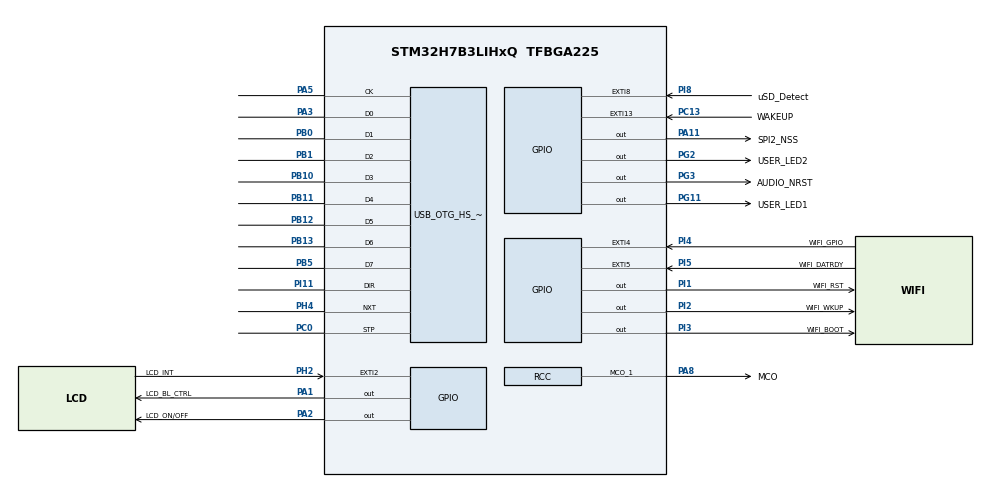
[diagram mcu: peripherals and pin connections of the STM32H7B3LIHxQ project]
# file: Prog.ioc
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Mcu.Family=STM32H7
Mcu.Name=STM32H7B3LIHxQ
Mcu.Package=TFBGA225
NVIC.PriorityGroup=NVIC_PRIORITYGROUP_4
PA1.GPIO_Label=LCD_BL_CTRL
PA1.PinState=GPIO_PIN_SET
PA1.Signal=GPIO_Output
PA10.GPIO_Label=VCP_RX
PA10.Signal=USART1_RX
PA11.GPIO_Label=SPI2_NSS
PA11.Signal=GPIO_Output
PA12.GPIO_Label=SPI2_SCK
PA12.Signal=SPI2_SCK
PA13.GPIO_Label=JTMS
PA13.Mode=JTAG_5_pins
PA13.Signal=DEBUG_JTMS-SWDIO
PA14.GPIO_Label=JTCK
PA14.Mode=JTAG_5_pins
PA14.Signal=DEBUG_JTCK-SWCLK
PA15.GPIO_Label=JTDI
PA15.Mode=JTAG_5_pins
PA15.Signal=DEBUG_JTDI
PA2.GPIO_Label=LCD_ON/OFF
PA2.PinState=GPIO_PIN_SET
PA2.Signal=GPIO_Output
PA3.Mode=Device_HS
PA3.Signal=USB_OTG_HS_ULPI_D0
PA5.Mode=Device_HS
PA5.Signal=USB_OTG_HS_ULPI_CK
PA8.GPIO_Label=MCO
PA8.Mode=Clock-out-1
PA8.Signal=RCC_MCO_1
PA9.GPIO_Label=VCP_TX
PA9.Signal=USART1_TX
PB0.Mode=Device_HS
PB0.Signal=USB_OTG_HS_ULPI_D1
PB1.Mode=Device_HS
PB1.Signal=USB_OTG_HS_ULPI_D2
PB10.Mode=Device_HS
PB10.Signal=USB_OTG_HS_ULPI_D3
PB11.Mode=Device_HS
PB11.Signal=USB_OTG_HS_ULPI_D4
PB12.Mode=Device_HS
PB12.Signal=USB_OTG_HS_ULPI_D5
PB13.Mode=Device_HS
PB13.Signal=USB_OTG_HS_ULPI_D6
PB2.GPIO_Label=OCSPI1_CLK
PB2.Signal=OCTOSPIM_P1_CLK
PB3.GPIO_Label=JTDO_TRACESWO
PB3.Mode=JTAG_5_pins
PB3.Signal=DEBUG_JTDO-SWO
PB4.Mode=JTAG_5_pins
PB4.Signal=DEBUG_JTRST
PB5.Mode=Device_HS
PB5.Signal=USB_OTG_HS_ULPI_D7
PC0.Mode=Device_HS
PC0.Signal=USB_OTG_HS_ULPI_STP
PC1.GPIO_Label=OCSPI1_IO4
PC1.Signal=OCTOSPIM_P1_IO4
PC10.GPIO_Label=SDIO1_D2
PC10.Signal=SDMMC1_D2
PC11.GPIO_Label=SDIO1_D3
PC11.Signal=SDMMC1_D3
PC12.GPIO_Label=SDIO1_CK
PC12.Signal=SDMMC1_CK
PC13.GPIO_Label=WAKEUP
PC13.Signal=GPXTI13
PC14-OSC32_IN.Mode=LSE-External-Oscillator
PC14-OSC32_IN.Signal=RCC_OSC32_IN
PC15-OSC32_OUT.Mode=LSE-External-Oscillator
PC15-OSC32_OUT.Signal=RCC_OSC32_OUT
PC2.GPIO_Label=SPI2_MISO
PC2.Signal=SPI2_MISO
PC3.GPIO_Label=SPI2_MOSI
PC3.Signal=SPI2_MOSI
PC5.GPIO_Label=OCSPI1_DQS
PC5.Signal=OCTOSPIM_P1_DQS
PC8.GPIO_Label=SDIO1_D0
PC8.Signal=SDMMC1_D0
PC9.GPIO_Label=SDIO1_D1
PC9.Signal=SDMMC1_D1
PD0.GPIO_Label=D2
PD0.Signal=FMC_D2_DA2
PD1.GPIO_Label=D3
PD1.Signal=FMC_D3_DA3
PD10.GPIO_Label=D15
PD10.Signal=FMC_D15_DA15
PD12.GPIO_Label=I2C4_SCL
PD12.GPIO_Pu=GPIO_PULLUP
PD12.Signal=I2C4_SCL
PD13.GPIO_Label=I2C4_SDA
PD13.GPIO_Pu=GPIO_PULLUP
PD13.Signal=I2C4_SDA
PD14.GPIO_Label=D0
PD14.Signal=FMC_D0_DA0
PD15.GPIO_Label=D1
PD15.Signal=FMC_D1_DA1
PD2.GPIO_Label=SDIO1_CMD
PD2.Signal=SDMMC1_CMD
PD7.GPIO_Label=OCSPI1_IO7
PD7.Signal=OCTOSPIM_P1_IO7
PD8.GPIO_Label=D13
PD8.Signal=FMC_D13_DA13
PD9.GPIO_Label=D14
PD9.Signal=FMC_D14_DA14
PE0.GPIO_Label=FMC_NBL0
PE0.Signal=FMC_NBL0
PE1.GPIO_Label=FMC_NBL1
PE1.Signal=FMC_NBL1
PE10.GPIO_Label=D7
PE10.Signal=FMC_D7_DA7
PE11.GPIO_Label=D8
PE11.Signal=FMC_D8_DA8
PE12.GPIO_Label=D9
PE12.Signal=FMC_D9_DA9
PE13.GPIO_Label=D10
PE13.Signal=FMC_D10_DA10
PE14.GPIO_Label=D11
PE14.Signal=FMC_D11_DA11
PE15.GPIO_Label=D12
PE15.Signal=FMC_D12_DA12
PE7.GPIO_Label=D4
PE7.Signal=FMC_D4_DA4
PE8.GPIO_Label=D5
PE8.Signal=FMC_D5_DA5
PE9.GPIO_Label=D6
PE9.Signal=FMC_D6_DA6
PF0.GPIO_Label=A0
PF0.Signal=FMC_A0
PF1.GPIO_Label=A1
PF1.Signal=FMC_A1
PF11.GPIO_Label=SDNRAS
PF11.Signal=FMC_SDNRAS
PF12.GPIO_Label=A6
PF12.Signal=FMC_A6
PF13.GPIO_Label=A7
PF13.Signal=FMC_A7
PF14.GPIO_Label=A8
PF14.Signal=FMC_A8
PF15.GPIO_Label=A9
PF15.Signal=FMC_A9
PF2.GPIO_Label=A2
PF2.Signal=FMC_A2
PF3.GPIO_Label=A3
PF3.Signal=FMC_A3
PF4.GPIO_Label=A4
PF4.Signal=FMC_A4
PF5.GPIO_Label=A5
PF5.Signal=FMC_A5
PG0.GPIO_Label=A10
PG0.Signal=FMC_A10
PG1.GPIO_Label=A11
PG1.Signal=FMC_A11
PG11.GPIO_Label=USER_LED1
PG11.Signal=GPIO_Output
PG15.GPIO_Label=SDNCAS
PG15.Signal=FMC_SDNCAS
PG2.GPIO_Label=USER_LED2
PG2.Signal=GPIO_Output
PG3.GPIO_Label=AUDIO_NRST
PG3.PinState=GPIO_PIN_SET
PG3.Signal=GPIO_Output
PG4.GPIO_Label=A14
PG4.Signal=FMC_A14_BA0
PG5.GPIO_Label=A15
PG5.Signal=FMC_A15_BA1
PG6.GPIO_Label=OCSPI1_NCS
PG6.Signal=OCTOSPIM_P1_NCS
PG8.GPIO_Label=SDCLK
PG8.Signal=FMC_SDCLK
PG9.GPIO_Label=OCSPI1_IO6
PG9.Signal=OCTOSPIM_P1_IO6
PH0-OSC_IN.Mode=HSE-External-Oscillator
PH0-OSC_IN.Signal=RCC_OSC_IN
PH1-OSC_OUT.Mode=HSE-External-Oscillator
PH1-OSC_OUT.Signal=RCC_OSC_OUT
PH2.GPIO_Label=LCD_INT
PH2.Signal=GPXTI2
PH3.GPIO_Label=OCSPI1_IO5
PH3.Signal=OCTOSPIM_P1_IO5
PH4.Mode=Device_HS
PH4.Signal=USB_OTG_HS_ULPI_NXT
PH5.GPIO_Label=SDNWE
PH5.Signal=FMC_SDNWE
PH6.GPIO_Label=SDNE1
PH6.Signal=FMC_SDNE1
PH7.GPIO_Label=SDCKE1
PH7.Signal=FMC_SDCKE1
PI1.GPIO_Label=WIFI_RST
PI1.Signal=GPIO_Output
PI11.Mode=Device_HS
PI11.Signal=USB_OTG_HS_ULPI_DIR
PI12.GPIO_Label=LCD_HSYNC
PI12.Signal=LTDC_HSYNC
PI13.GPIO_Label=LCD_VSYNC
PI13.Signal=LTDC_VSYNC
PI14.GPIO_Label=LCD_CLK
PI14.Signal=LTDC_CLK
PI15.GPIO_Label=LCD_R0
PI15.Signal=LTDC_R0
PI2.GPIO_Label=WIFI_WKUP
PI2.Signal=GPIO_Output
PI3.GPIO_Label=WIFI_BOOT
PI3.Signal=GPIO_Output
PI4.GPIO_Label=WIFI_GPIO
PI4.Signal=GPXTI4
PI5.GPIO_Label=WIFI_DATRDY
PI5.Signal=GPXTI5
PI8.GPIO_Label=uSD_Detect
PI8.GPIO_PuPd=GPIO_PULLUP
PI8.Signal=GPXTI8
PJ0.GPIO_Label=LCD_R1
PJ0.Signal=LTDC_R1
PJ1.GPIO_Label=LCD_R2
PJ1.Signal=LTDC_R2
PJ10.GPIO_Label=LCD_G3
PJ10.Signal=LTDC_G3
PJ11.GPIO_Label=LCD_G4
PJ11.Signal=LTDC_G4
PJ12.GPIO_Label=LCD_B0
PJ12.Signal=LTDC_B0
PJ13.GPIO_Label=LCD_B1
PJ13.Signal=LTDC_B1
PJ14.GPIO_Label=LCD_B2
PJ14.Signal=LTDC_B2
PJ15.GPIO_Label=LCD_B3
PJ15.Signal=LTDC_B3
PJ2.GPIO_Label=LCD_R3
PJ2.Signal=LTDC_R3
PJ3.GPIO_Label=LCD_R4
PJ3.Signal=LTDC_R4
PJ4.GPIO_Label=LCD_R5
PJ4.Signal=LTDC_R5
PJ5.GPIO_Label=LCD_R6
PJ5.Signal=LTDC_R6
PJ6.GPIO_Label=LCD_R7
PJ6.Signal=LTDC_R7
PJ7.GPIO_Label=LCD_G0
PJ7.Signal=LTDC_G0
PJ8.GPIO_Label=LCD_G1
PJ8.Signal=LTDC_G1
PJ9.GPIO_Label=LCD_G2
PJ9.Signal=LTDC_G2
PK0.GPIO_Label=LCD_G5
PK0.Signal=LTDC_G5
PK1.GPIO_Label=LCD_G6
PK1.Signal=LTDC_G6
PK2.GPIO_Label=LCD_G7
PK2.Signal=LTDC_G7
PK3.GPIO_Label=LCD_B4
PK3.Signal=LTDC_B4
PK4.GPIO_Label=LCD_B5
PK4.Signal=LTDC_B5
PK5.GPIO_Label=LCD_B6
PK5.Signal=LTDC_B6
PK6.GPIO_Label=LCD_B7
PK6.Signal=LTDC_B7
PK7.GPIO_Label=LCD_DE
PK7.Signal=LTDC_DE
ProjectManager.HeapSize=0x200
ProjectManager.StackSize=0x400
ProjectManager.TargetToolchain=STM32CubeIDE
RCC.ADCFreq_Value=64000488.28125
RCC.APB1Freq_Value=72000000
RCC.APB2Freq_Value=72000000
RCC.APB3Freq_Value=72000000
RCC.APB4Freq_Value=72000000
RCC.CortexFreq_Value=72000000
RCC.DIVM1=2
RCC.DIVM2=2
RCC.DIVM3=2
RCC.DIVN1=12
RCC.DIVN2=10
RCC.DIVN3=12
RCC.DIVP3=17
RCC.DIVQ1=3
RCC.DIVR1=4
RCC.DIVR2=1
RCC.DIVR3=1
RCC.FMCCLockSelection=RCC_FMCCLKSOURCE_PLL2
RCC.HCLKFreq_Value=72000000
RCC.PLL2FRACN=5462
RCC.PLL3FRACN=4096
RCC.PLLFRACN=0
RCC.PLLSourceVirtual=RCC_PLLSOURCE_HSE
RCC.PWR_Regulator_Voltage_Scale=PWR_REGULATOR_VOLTAGE_SCALE0
RCC.QSPICLockSelection=RCC_OSPICLKSOURCE_PLL2
RCC.RCC_MCO1Source=RCC_MCO1SOURCE_HSE
RCC.RTCClockSelection=RCC_RTCCLKSOURCE_LSE
RCC.SDMMC1CLockSelection=RCC_SDMMCCLKSOURCE_PLL2
RCC.SPI123CLockSelection=RCC_SPI123CLKSOURCE_CLKP
RCC.SYSCLKFreq_VALUE=72000000
RCC.SYSCLKSource=RCC_SYSCLKSOURCE_PLLCLK
RCC.SupplySource=PWR_DIRECT_SMPS_SUPPLY
RCC.USBFreq_Value=48000000
SH.FMC_A0.0=FMC_A0
SH.FMC_A1.0=FMC_A1
SH.FMC_A10.0=FMC_A10
SH.FMC_A11.0=FMC_A11
SH.FMC_A14_BA0.0=FMC_BA0
SH.FMC_A15_BA1.0=FMC_BA1
SH.FMC_A2.0=FMC_A2
SH.FMC_A3.0=FMC_A3
SH.FMC_A4.0=FMC_A4
SH.FMC_A5.0=FMC_A5
SH.FMC_A6.0=FMC_A6
SH.FMC_A7.0=FMC_A7
SH.FMC_A8.0=FMC_A8
SH.FMC_A9.0=FMC_A9
SH.FMC_D0_DA0.0=FMC_D0
SH.FMC_D10_DA10.0=FMC_D10
SH.FMC_D11_DA11.0=FMC_D11
SH.FMC_D12_DA12.0=FMC_D12
SH.FMC_D13_DA13.0=FMC_D13
SH.FMC_D14_DA14.0=FMC_D14
SH.FMC_D15_DA15.0=FMC_D15
SH.FMC_D1_DA1.0=FMC_D1
SH.FMC_D2_DA2.0=FMC_D2
SH.FMC_D3_DA3.0=FMC_D3
SH.FMC_D4_DA4.0=FMC_D4
SH.FMC_D5_DA5.0=FMC_D5
SH.FMC_D6_DA6.0=FMC_D6
SH.FMC_D7_DA7.0=FMC_D7
SH.FMC_D8_DA8.0=FMC_D8
SH.FMC_D9_DA9.0=FMC_D9
SH.FMC_NBL0.0=FMC_NBL0
SH.FMC_NBL1.0=FMC_NBL1
SH.FMC_SDCLK.0=FMC_SDCLK
SH.FMC_SDNCAS.0=FMC_SDNCAS
SH.FMC_SDNRAS.0=FMC_SDNRAS
SH.FMC_SDNWE.0=FMC_SDNWE
USB_OTG_HS.DeviceSpeed-Device_HS=PCD_SPEED_FULL
USB_OTG_HS.VirtualMode-Device_HS=Device_HS
board=STM32H7B3I-DK

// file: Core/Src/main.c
/* USER CODE BEGIN Header */
/**
  ******************************************************************************
  * @file           : main.c
  * @brief          : Main program body
  ******************************************************************************
  * @attention
  *
  * <h2><center>&copy; Copyright (c) 2020 STMicroelectronics.
  * All rights reserved.</center></h2>
  *
  * This software component is licensed by ST under BSD 3-Clause license,
  * the "License"; You may not use this file except in compliance with the
  * License. You may obtain a copy of the License at:
  *                        opensource.org/licenses/BSD-3-Clause
  *
  ******************************************************************************
  */
/* USER CODE END Header */
#include "main.h"

/* USER CODE BEGIN Includes */
#include "header.h"
/* USER CODE END Includes */

PCD_HandleTypeDef hpcd_USB_OTG_HS;

void SystemClock_Config(void);
static void MX_GPIO_Init(void);
static void MX_USB_OTG_HS_PCD_Init(void);

/* USER CODE BEGIN 0 */
/**
  * @brief  Vector base address configuration. It should no longer be at the start of
  *         flash memory but moved forward because the first part of flash is
  *         reserved for the bootloader. Note that this is already done by the
  *         bootloader before starting this program. Unfortunately, function
  *         SystemInit() overwrites this change again.
  * @return none.
  */
static void VectorBase_Config(void)
{
  /* The constant array with vectors of the vector table is declared externally in the
   * c-startup code.
   */
  extern const unsigned long g_pfnVectors[];

  /* Remap the vector table to where the vector table is located for this program. */
  SCB->VTOR = (unsigned long)&g_pfnVectors[0];
}
/* USER CODE END 0 */

int main(void)
{
  /* USER CODE BEGIN 1 */
  /* Configure the vector table base address. */
  VectorBase_Config();
  /* USER CODE END 1 */

  /* MCU Configuration--------------------------------------------------------*/

  /* Reset of all peripherals, Initializes the Flash interface and the Systick. */
  HAL_Init();

  /* Configure the system clock */
  SystemClock_Config();

  /* Initialize all configured peripherals */
  MX_GPIO_Init();
  MX_USB_OTG_HS_PCD_Init();
  /* USER CODE BEGIN 2 */
  /* Initialize the user program application. */
  AppInit();
  /* USER CODE END 2 */

  /* Infinite loop */
  /* USER CODE BEGIN WHILE */
  while (1)
  {
    /* Run the user program application. */
    AppTask();
    /* USER CODE END WHILE */

  }
}

void SystemClock_Config(void)
{

  /*AXI clock gating */
  RCC->CKGAENR = 0xFFFFFFFF;

  LL_FLASH_SetLatency(LL_FLASH_LATENCY_1);
  while(LL_FLASH_GetLatency()!= LL_FLASH_LATENCY_1)
  {
  }
  LL_PWR_ConfigSupply(LL_PWR_DIRECT_SMPS_SUPPLY);
  LL_PWR_SetRegulVoltageScaling(LL_PWR_REGU_VOLTAGE_SCALE0);
  LL_RCC_HSE_Enable();

   /* Wait till HSE is ready */
  while(LL_RCC_HSE_IsReady() != 1)
  {

  }
  LL_RCC_PLL_SetSource(LL_RCC_PLLSOURCE_HSE);
  LL_RCC_PLL1P_Enable();
  LL_RCC_PLL1Q_Enable();
  LL_RCC_PLL1R_Enable();
  LL_RCC_PLL1_SetVCOInputRange(LL_RCC_PLLINPUTRANGE_8_16);
  LL_RCC_PLL1_SetVCOOutputRange(LL_RCC_PLLVCORANGE_WIDE);
  LL_RCC_PLL1_SetM(2);
  LL_RCC_PLL1_SetN(12);
  LL_RCC_PLL1_SetP(2);
  LL_RCC_PLL1_SetQ(3);
  LL_RCC_PLL1_SetR(4);
  LL_RCC_PLL1_Enable();

   /* Wait till PLL is ready */
  while(LL_RCC_PLL1_IsReady() != 1)
  {
  }

  LL_RCC_SetSysClkSource(LL_RCC_SYS_CLKSOURCE_PLL1);

   /* Wait till System clock is ready */
  while(LL_RCC_GetSysClkSource() != LL_RCC_SYS_CLKSOURCE_STATUS_PLL1)
  {

  }
  LL_RCC_SetAHBPrescaler(LL_RCC_AHB_DIV_1);
  LL_RCC_SetAPB1Prescaler(LL_RCC_APB1_DIV_1);
  LL_RCC_SetAPB2Prescaler(LL_RCC_APB2_DIV_1);
  LL_RCC_SetAPB3Prescaler(LL_RCC_APB3_DIV_1);
  LL_RCC_SetAPB4Prescaler(LL_RCC_APB4_DIV_1);
  LL_SetSystemCoreClock(72000000);

   /* Update the time base */
  if (HAL_InitTick (TICK_INT_PRIORITY) != HAL_OK)
  {
    Error_Handler();
  }
  LL_RCC_ConfigMCO(LL_RCC_MCO1SOURCE_HSE, LL_RCC_MCO1_DIV_1);
}

static void MX_USB_OTG_HS_PCD_Init(void)
{

  hpcd_USB_OTG_HS.Instance = USB_OTG_HS;
  hpcd_USB_OTG_HS.Init.dev_endpoints = 9;
  hpcd_USB_OTG_HS.Init.speed = PCD_SPEED_FULL;
  hpcd_USB_OTG_HS.Init.dma_enable = DISABLE;
  hpcd_USB_OTG_HS.Init.phy_itface = USB_OTG_ULPI_PHY;
  hpcd_USB_OTG_HS.Init.Sof_enable = DISABLE;
  hpcd_USB_OTG_HS.Init.low_power_enable = DISABLE;
  hpcd_USB_OTG_HS.Init.lpm_enable = DISABLE;
  hpcd_USB_OTG_HS.Init.vbus_sensing_enable = DISABLE;
  hpcd_USB_OTG_HS.Init.use_dedicated_ep1 = DISABLE;
  hpcd_USB_OTG_HS.Init.use_external_vbus = DISABLE;
  if (HAL_PCD_Init(&hpcd_USB_OTG_HS) != HAL_OK)
  {
    Error_Handler();
  }

}

static void MX_GPIO_Init(void)
{
  LL_EXTI_InitTypeDef EXTI_InitStruct = {0};
  LL_GPIO_InitTypeDef GPIO_InitStruct = {0};

  /* GPIO Ports Clock Enable */
  LL_AHB4_GRP1_EnableClock(LL_AHB4_GRP1_PERIPH_GPIOI);
  LL_AHB4_GRP1_EnableClock(LL_AHB4_GRP1_PERIPH_GPIOG);
  LL_AHB4_GRP1_EnableClock(LL_AHB4_GRP1_PERIPH_GPIOK);
  LL_AHB4_GRP1_EnableClock(LL_AHB4_GRP1_PERIPH_GPIOD);
  LL_AHB4_GRP1_EnableClock(LL_AHB4_GRP1_PERIPH_GPIOC);
  LL_AHB4_GRP1_EnableClock(LL_AHB4_GRP1_PERIPH_GPIOE);
  LL_AHB4_GRP1_EnableClock(LL_AHB4_GRP1_PERIPH_GPIOB);
  LL_AHB4_GRP1_EnableClock(LL_AHB4_GRP1_PERIPH_GPIOJ);
  LL_AHB4_GRP1_EnableClock(LL_AHB4_GRP1_PERIPH_GPIOA);
  LL_AHB4_GRP1_EnableClock(LL_AHB4_GRP1_PERIPH_GPIOF);
  LL_AHB4_GRP1_EnableClock(LL_AHB4_GRP1_PERIPH_GPIOH);

  /**/
  LL_GPIO_ResetOutputPin(GPIOI, WIFI_BOOT_Pin|WIFI_WKUP_Pin|WIFI_RST_Pin);

  /**/
  LL_GPIO_ResetOutputPin(GPIOG, USER_LED1_Pin|USER_LED2_Pin);

  /**/
  LL_GPIO_ResetOutputPin(SPI2_NSS_GPIO_Port, SPI2_NSS_Pin);

  /**/
  LL_GPIO_SetOutputPin(AUDIO_NRST_GPIO_Port, AUDIO_NRST_Pin);

  /**/
  LL_GPIO_SetOutputPin(GPIOA, LCD_BL_CTRL_Pin|LCD_ON_OFF_Pin);

  /**/
  LL_SYSCFG_SetEXTISource(LL_SYSCFG_EXTI_PORTI, LL_SYSCFG_EXTI_LINE4);

  /**/
  LL_SYSCFG_SetEXTISource(LL_SYSCFG_EXTI_PORTI, LL_SYSCFG_EXTI_LINE5);

  /**/
  LL_SYSCFG_SetEXTISource(LL_SYSCFG_EXTI_PORTI, LL_SYSCFG_EXTI_LINE8);

  /**/
  LL_SYSCFG_SetEXTISource(LL_SYSCFG_EXTI_PORTC, LL_SYSCFG_EXTI_LINE13);

  /**/
  LL_SYSCFG_SetEXTISource(LL_SYSCFG_EXTI_PORTH, LL_SYSCFG_EXTI_LINE2);

  /**/
  EXTI_InitStruct.Line_0_31 = LL_EXTI_LINE_4;
  EXTI_InitStruct.Line_32_63 = LL_EXTI_LINE_NONE;
  EXTI_InitStruct.Line_64_95 = LL_EXTI_LINE_NONE;
  EXTI_InitStruct.LineCommand = ENABLE;
  EXTI_InitStruct.Mode = LL_EXTI_MODE_IT;
  EXTI_InitStruct.Trigger = LL_EXTI_TRIGGER_RISING;
  LL_EXTI_Init(&EXTI_InitStruct);

  /**/
  EXTI_InitStruct.Line_0_31 = LL_EXTI_LINE_5;
  EXTI_InitStruct.Line_32_63 = LL_EXTI_LINE_NONE;
  EXTI_InitStruct.Line_64_95 = LL_EXTI_LINE_NONE;
  EXTI_InitStruct.LineCommand = ENABLE;
  EXTI_InitStruct.Mode = LL_EXTI_MODE_IT;
  EXTI_InitStruct.Trigger = LL_EXTI_TRIGGER_RISING;
  LL_EXTI_Init(&EXTI_InitStruct);

  /**/
  EXTI_InitStruct.Line_0_31 = LL_EXTI_LINE_8;
  EXTI_InitStruct.Line_32_63 = LL_EXTI_LINE_NONE;
  EXTI_InitStruct.Line_64_95 = LL_EXTI_LINE_NONE;
  EXTI_InitStruct.LineCommand = ENABLE;
  EXTI_InitStruct.Mode = LL_EXTI_MODE_IT;
  EXTI_InitStruct.Trigger = LL_EXTI_TRIGGER_RISING;
  LL_EXTI_Init(&EXTI_InitStruct);

  /**/
  EXTI_InitStruct.Line_0_31 = LL_EXTI_LINE_13;
  EXTI_InitStruct.Line_32_63 = LL_EXTI_LINE_NONE;
  EXTI_InitStruct.Line_64_95 = LL_EXTI_LINE_NONE;
  EXTI_InitStruct.LineCommand = ENABLE;
  EXTI_InitStruct.Mode = LL_EXTI_MODE_IT;
  EXTI_InitStruct.Trigger = LL_EXTI_TRIGGER_RISING;
  LL_EXTI_Init(&EXTI_InitStruct);

  /**/
  EXTI_InitStruct.Line_0_31 = LL_EXTI_LINE_2;
  EXTI_InitStruct.Line_32_63 = LL_EXTI_LINE_NONE;
  EXTI_InitStruct.Line_64_95 = LL_EXTI_LINE_NONE;
  EXTI_InitStruct.LineCommand = ENABLE;
  EXTI_InitStruct.Mode = LL_EXTI_MODE_IT;
  EXTI_InitStruct.Trigger = LL_EXTI_TRIGGER_RISING;
  LL_EXTI_Init(&EXTI_InitStruct);

  /**/
  LL_GPIO_SetPinPull(WIFI_GPIO_GPIO_Port, WIFI_GPIO_Pin, LL_GPIO_PULL_NO);

  /**/
  LL_GPIO_SetPinPull(WIFI_DATRDY_GPIO_Port, WIFI_DATRDY_Pin, LL_GPIO_PULL_NO);

  /**/
  LL_GPIO_SetPinPull(uSD_Detect_GPIO_Port, uSD_Detect_Pin, LL_GPIO_PULL_UP);

  /**/
  LL_GPIO_SetPinPull(WAKEUP_GPIO_Port, WAKEUP_Pin, LL_GPIO_PULL_NO);

  /**/
  LL_GPIO_SetPinPull(LCD_INT_GPIO_Port, LCD_INT_Pin, LL_GPIO_PULL_NO);

  /**/
  LL_GPIO_SetPinMode(WIFI_GPIO_GPIO_Port, WIFI_GPIO_Pin, LL_GPIO_MODE_INPUT);

  /**/
  LL_GPIO_SetPinMode(WIFI_DATRDY_GPIO_Port, WIFI_DATRDY_Pin, LL_GPIO_MODE_INPUT);

  /**/
  LL_GPIO_SetPinMode(uSD_Detect_GPIO_Port, uSD_Detect_Pin, LL_GPIO_MODE_INPUT);

  /**/
  LL_GPIO_SetPinMode(WAKEUP_GPIO_Port, WAKEUP_Pin, LL_GPIO_MODE_INPUT);

  /**/
  LL_GPIO_SetPinMode(LCD_INT_GPIO_Port, LCD_INT_Pin, LL_GPIO_MODE_INPUT);

  /**/
  GPIO_InitStruct.Pin = SDNCAS_Pin|SDCLK_Pin|A15_Pin|A14_Pin
                          |A11_Pin|A10_Pin;
  GPIO_InitStruct.Mode = LL_GPIO_MODE_ALTERNATE;
  GPIO_InitStruct.Speed = LL_GPIO_SPEED_FREQ_VERY_HIGH;
  GPIO_InitStruct.OutputType = LL_GPIO_OUTPUT_PUSHPULL;
  GPIO_InitStruct.Pull = LL_GPIO_PULL_NO;
  GPIO_InitStruct.Alternate = LL_GPIO_AF_12;
  LL_GPIO_Init(GPIOG, &GPIO_InitStruct);

  /**/
  GPIO_InitStruct.Pin = LCD_B6_Pin|LCD_B7_Pin|LCD_B4_Pin|LCD_B5_Pin
                          |LCD_DE_Pin|LCD_G7_Pin|LCD_G6_Pin|LCD_G5_Pin;
  GPIO_InitStruct.Mode = LL_GPIO_MODE_ALTERNATE;
  GPIO_InitStruct.Speed = LL_GPIO_SPEED_FREQ_LOW;
  GPIO_InitStruct.OutputType = LL_GPIO_OUTPUT_PUSHPULL;
  GPIO_InitStruct.Pull = LL_GPIO_PULL_NO;
  GPIO_InitStruct.Alternate = LL_GPIO_AF_14;
  LL_GPIO_Init(GPIOK, &GPIO_InitStruct);

  /**/
  GPIO_InitStruct.Pin = OCSPI1_IO6_Pin;
  GPIO_InitStruct.Mode = LL_GPIO_MODE_ALTERNATE;
  GPIO_InitStruct.Speed = LL_GPIO_SPEED_FREQ_VERY_HIGH;
  GPIO_InitStruct.OutputType = LL_GPIO_OUTPUT_PUSHPULL;
  GPIO_InitStruct.Pull = LL_GPIO_PULL_NO;
  GPIO_InitStruct.Alternate = LL_GPIO_AF_9;
  LL_GPIO_Init(OCSPI1_IO6_GPIO_Port, &GPIO_InitStruct);

  /**/
  GPIO_InitStruct.Pin = OCSPI1_IO7_Pin;
  GPIO_InitStruct.Mode = LL_GPIO_MODE_ALTERNATE;
  GPIO_InitStruct.Speed = LL_GPIO_SPEED_FREQ_VERY_HIGH;
  GPIO_InitStruct.OutputType = LL_GPIO_OUTPUT_PUSHPULL;
  GPIO_InitStruct.Pull = LL_GPIO_PULL_NO;
  GPIO_InitStruct.Alternate = LL_GPIO_AF_10;
  LL_GPIO_Init(OCSPI1_IO7_GPIO_Port, &GPIO_InitStruct);

  /**/
  GPIO_InitStruct.Pin = D3_Pin|SDIO1_CMD_Pin|D2_Pin|D0_Pin
                          |D1_Pin|D13_Pin|D15_Pin|D14_Pin;
  GPIO_InitStruct.Mode = LL_GPIO_MODE_ALTERNATE;
  GPIO_InitStruct.Speed = LL_GPIO_SPEED_FREQ_VERY_HIGH;
  GPIO_InitStruct.OutputType = LL_GPIO_OUTPUT_PUSHPULL;
  GPIO_InitStruct.Pull = LL_GPIO_PULL_NO;
  GPIO_InitStruct.Alternate = LL_GPIO_AF_12;
  LL_GPIO_Init(GPIOD, &GPIO_InitStruct);

  /**/
  GPIO_InitStruct.Pin = SDIO1_D2_Pin|SDIO1_CK_Pin|SDIO1_D3_Pin|SDIO1_D1_Pin
                          |SDIO1_D0_Pin;
  GPIO_InitStruct.Mode = LL_GPIO_MODE_ALTERNATE;
  GPIO_InitStruct.Speed = LL_GPIO_SPEED_FREQ_VERY_HIGH;
  GPIO_InitStruct.OutputType = LL_GPIO_OUTPUT_PUSHPULL;
  GPIO_InitStruct.Pull = LL_GPIO_PULL_NO;
  GPIO_InitStruct.Alternate = LL_GPIO_AF_12;
  LL_GPIO_Init(GPIOC, &GPIO_InitStruct);

  /**/
  GPIO_InitStruct.Pin = WIFI_BOOT_Pin|WIFI_WKUP_Pin|WIFI_RST_Pin;
  GPIO_InitStruct.Mode = LL_GPIO_MODE_OUTPUT;
  GPIO_InitStruct.Speed = LL_GPIO_SPEED_FREQ_LOW;
  GPIO_InitStruct.OutputType = LL_GPIO_OUTPUT_PUSHPULL;
  GPIO_InitStruct.Pull = LL_GPIO_PULL_NO;
  LL_GPIO_Init(GPIOI, &GPIO_InitStruct);

  /**/
  GPIO_InitStruct.Pin = FMC_NBL0_Pin|FMC_NBL1_Pin|D9_Pin|D4_Pin
                          |D10_Pin|D11_Pin|D7_Pin|D6_Pin
                          |D12_Pin|D5_Pin|D8_Pin;
  GPIO_InitStruct.Mode = LL_GPIO_MODE_ALTERNATE;
  GPIO_InitStruct.Speed = LL_GPIO_SPEED_FREQ_VERY_HIGH;
  GPIO_InitStruct.OutputType = LL_GPIO_OUTPUT_PUSHPULL;
  GPIO_InitStruct.Pull = LL_GPIO_PULL_NO;
  GPIO_InitStruct.Alternate = LL_GPIO_AF_12;
  LL_GPIO_Init(GPIOE, &GPIO_InitStruct);

  /**/
  GPIO_InitStruct.Pin = USER_LED1_Pin|AUDIO_NRST_Pin|USER_LED2_Pin;
  GPIO_InitStruct.Mode = LL_GPIO_MODE_OUTPUT;
  GPIO_InitStruct.Speed = LL_GPIO_SPEED_FREQ_LOW;
  GPIO_InitStruct.OutputType = LL_GPIO_OUTPUT_PUSHPULL;
  GPIO_InitStruct.Pull = LL_GPIO_PULL_NO;
  LL_GPIO_Init(GPIOG, &GPIO_InitStruct);

  /**/
  GPIO_InitStruct.Pin = LCD_B3_Pin|LCD_B2_Pin|LCD_B1_Pin|LCD_B0_Pin
                          |LCD_G4_Pin|LCD_G3_Pin|LCD_G2_Pin|LCD_G1_Pin
                          |LCD_R7_Pin|LCD_G0_Pin|LCD_R1_Pin|LCD_R6_Pin
                          |LCD_R2_Pin|LCD_R5_Pin|LCD_R3_Pin|LCD_R4_Pin;
  GPIO_InitStruct.Mode = LL_GPIO_MODE_ALTERNATE;
  GPIO_InitStruct.Speed = LL_GPIO_SPEED_FREQ_LOW;
  GPIO_InitStruct.OutputType = LL_GPIO_OUTPUT_PUSHPULL;
  GPIO_InitStruct.Pull = LL_GPIO_PULL_NO;
  GPIO_InitStruct.Alternate = LL_GPIO_AF_14;
  LL_GPIO_Init(GPIOJ, &GPIO_InitStruct);

  /**/
  GPIO_InitStruct.Pin = SPI2_SCK_Pin;
  GPIO_InitStruct.Mode = LL_GPIO_MODE_ALTERNATE;
  GPIO_InitStruct.Speed = LL_GPIO_SPEED_FREQ_LOW;
  GPIO_InitStruct.OutputType = LL_GPIO_OUTPUT_PUSHPULL;
  GPIO_InitStruct.Pull = LL_GPIO_PULL_NO;
  GPIO_InitStruct.Alternate = LL_GPIO_AF_5;
  LL_GPIO_Init(SPI2_SCK_GPIO_Port, &GPIO_InitStruct);

  /**/
  GPIO_InitStruct.Pin = SPI2_NSS_Pin|LCD_BL_CTRL_Pin|LCD_ON_OFF_Pin;
  GPIO_InitStruct.Mode = LL_GPIO_MODE_OUTPUT;
  GPIO_InitStruct.Speed = LL_GPIO_SPEED_FREQ_LOW;
  GPIO_InitStruct.OutputType = LL_GPIO_OUTPUT_PUSHPULL;
  GPIO_InitStruct.Pull = LL_GPIO_PULL_NO;
  LL_GPIO_Init(GPIOA, &GPIO_InitStruct);

  /**/
  GPIO_InitStruct.Pin = VCP_RX_Pin|VCP_TX_Pin;
  GPIO_InitStruct.Mode = LL_GPIO_MODE_ALTERNATE;
  GPIO_InitStruct.Speed = LL_GPIO_SPEED_FREQ_LOW;
  GPIO_InitStruct.OutputType = LL_GPIO_OUTPUT_PUSHPULL;
  GPIO_InitStruct.Pull = LL_GPIO_PULL_NO;
  GPIO_InitStruct.Alternate = LL_GPIO_AF_7;
  LL_GPIO_Init(GPIOA, &GPIO_InitStruct);

  /**/
  GPIO_InitStruct.Pin = A1_Pin|A0_Pin|A2_Pin|A4_Pin
                          |A3_Pin|A5_Pin|A7_Pin|SDNRAS_Pin
                          |A9_Pin|A8_Pin|A6_Pin;
  GPIO_InitStruct.Mode = LL_GPIO_MODE_ALTERNATE;
  GPIO_InitStruct.Speed = LL_GPIO_SPEED_FREQ_VERY_HIGH;
  GPIO_InitStruct.OutputType = LL_GPIO_OUTPUT_PUSHPULL;
  GPIO_InitStruct.Pull = LL_GPIO_PULL_NO;
  GPIO_InitStruct.Alternate = LL_GPIO_AF_12;
  LL_GPIO_Init(GPIOF, &GPIO_InitStruct);

  /**/
  GPIO_InitStruct.Pin = MCO_Pin;
  GPIO_InitStruct.Mode = LL_GPIO_MODE_ALTERNATE;
  GPIO_InitStruct.Speed = LL_GPIO_SPEED_FREQ_LOW;
  GPIO_InitStruct.OutputType = LL_GPIO_OUTPUT_PUSHPULL;
  GPIO_InitStruct.Pull = LL_GPIO_PULL_NO;
  GPIO_InitStruct.Alternate = LL_GPIO_AF_0;
  LL_GPIO_Init(MCO_GPIO_Port, &GPIO_InitStruct);

  /**/
  GPIO_InitStruct.Pin = OCSPI1_NCS_Pin;
  GPIO_InitStruct.Mode = LL_GPIO_MODE_ALTERNATE;
  GPIO_InitStruct.Speed = LL_GPIO_SPEED_FREQ_VERY_HIGH;
  GPIO_InitStruct.OutputType = LL_GPIO_OUTPUT_PUSHPULL;
  GPIO_InitStruct.Pull = LL_GPIO_PULL_NO;
  GPIO_InitStruct.Alternate = LL_GPIO_AF_10;
  LL_GPIO_Init(OCSPI1_NCS_GPIO_Port, &GPIO_InitStruct);

  /**/
  GPIO_InitStruct.Pin = LCD_HSYNC_Pin|LCD_CLK_Pin|LCD_VSYNC_Pin|LCD_R0_Pin;
  GPIO_InitStruct.Mode = LL_GPIO_MODE_ALTERNATE;
  GPIO_InitStruct.Speed = LL_GPIO_SPEED_FREQ_LOW;
  GPIO_InitStruct.OutputType = LL_GPIO_OUTPUT_PUSHPULL;
  GPIO_InitStruct.Pull = LL_GPIO_PULL_NO;
  GPIO_InitStruct.Alternate = LL_GPIO_AF_14;
  LL_GPIO_Init(GPIOI, &GPIO_InitStruct);

  /**/
  GPIO_InitStruct.Pin = SPI2_MISO_Pin|SPI2_MOSI_Pin;
  GPIO_InitStruct.Mode = LL_GPIO_MODE_ALTERNATE;
  GPIO_InitStruct.Speed = LL_GPIO_SPEED_FREQ_LOW;
  GPIO_InitStruct.OutputType = LL_GPIO_OUTPUT_PUSHPULL;
  GPIO_InitStruct.Pull = LL_GPIO_PULL_NO;
  GPIO_InitStruct.Alternate = LL_GPIO_AF_5;
  LL_GPIO_Init(GPIOC, &GPIO_InitStruct);

  /**/
  GPIO_InitStruct.Pin = I2C4_SDA_Pin|I2C4_SCL_Pin;
  GPIO_InitStruct.Mode = LL_GPIO_MODE_ALTERNATE;
  GPIO_InitStruct.Speed = LL_GPIO_SPEED_FREQ_LOW;
  GPIO_InitStruct.OutputType = LL_GPIO_OUTPUT_OPENDRAIN;
  GPIO_InitStruct.Pull = LL_GPIO_PULL_UP;
  GPIO_InitStruct.Alternate = LL_GPIO_AF_4;
  LL_GPIO_Init(GPIOD, &GPIO_InitStruct);

  /**/
  GPIO_InitStruct.Pin = OCSPI1_IO4_Pin|OCSPI1_DQS_Pin;
  GPIO_InitStruct.Mode = LL_GPIO_MODE_ALTERNATE;
  GPIO_InitStruct.Speed = LL_GPIO_SPEED_FREQ_VERY_HIGH;
  GPIO_InitStruct.OutputType = LL_GPIO_OUTPUT_PUSHPULL;
  GPIO_InitStruct.Pull = LL_GPIO_PULL_NO;
  GPIO_InitStruct.Alternate = LL_GPIO_AF_10;
  LL_GPIO_Init(GPIOC, &GPIO_InitStruct);

  /**/
  GPIO_InitStruct.Pin = SDNE1_Pin|SDNWE_Pin|SDCKE1_Pin;
  GPIO_InitStruct.Mode = LL_GPIO_MODE_ALTERNATE;
  GPIO_InitStruct.Speed = LL_GPIO_SPEED_FREQ_VERY_HIGH;
  GPIO_InitStruct.OutputType = LL_GPIO_OUTPUT_PUSHPULL;
  GPIO_InitStruct.Pull = LL_GPIO_PULL_NO;
  GPIO_InitStruct.Alternate = LL_GPIO_AF_12;
  LL_GPIO_Init(GPIOH, &GPIO_InitStruct);

  /**/
  GPIO_InitStruct.Pin = OCSPI1_IO5_Pin;
  GPIO_InitStruct.Mode = LL_GPIO_MODE_ALTERNATE;
  GPIO_InitStruct.Speed = LL_GPIO_SPEED_FREQ_VERY_HIGH;
  GPIO_InitStruct.OutputType = LL_GPIO_OUTPUT_PUSHPULL;
  GPIO_InitStruct.Pull = LL_GPIO_PULL_NO;
  GPIO_InitStruct.Alternate = LL_GPIO_AF_9;
  LL_GPIO_Init(OCSPI1_IO5_GPIO_Port, &GPIO_InitStruct);

  /**/
  GPIO_InitStruct.Pin = OCSPI1_CLK_Pin;
  GPIO_InitStruct.Mode = LL_GPIO_MODE_ALTERNATE;
  GPIO_InitStruct.Speed = LL_GPIO_SPEED_FREQ_VERY_HIGH;
  GPIO_InitStruct.OutputType = LL_GPIO_OUTPUT_PUSHPULL;
  GPIO_InitStruct.Pull = LL_GPIO_PULL_NO;
  GPIO_InitStruct.Alternate = LL_GPIO_AF_9;
  LL_GPIO_Init(OCSPI1_CLK_GPIO_Port, &GPIO_InitStruct);

}

void Error_Handler(void)
{
}
